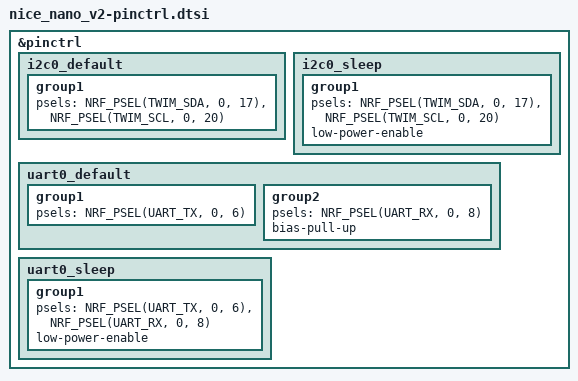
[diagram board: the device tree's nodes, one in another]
/*
 * Copyright (c) 2026 Wafer Pad contributors
 * SPDX-License-Identifier: Apache-2.0
 */

&pinctrl {
	/* Pro Micro I2C pins: D2 = P0.17 (SDA), D3 = P0.20 (SCL).
	 * The nice!nano v2 has NO on-board I2C pull-ups.
	 */
	i2c0_default: i2c0_default {
		group1 {
			psels = <NRF_PSEL(TWIM_SDA, 0, 17)>,
				<NRF_PSEL(TWIM_SCL, 0, 20)>;
		};
	};

	i2c0_sleep: i2c0_sleep {
		group1 {
			psels = <NRF_PSEL(TWIM_SDA, 0, 17)>,
				<NRF_PSEL(TWIM_SCL, 0, 20)>;
			low-power-enable;
		};
	};

	/* Pro Micro serial pins: D1 = P0.06 (TX), D0 = P0.08 (RX). */
	uart0_default: uart0_default {
		group1 {
			psels = <NRF_PSEL(UART_TX, 0, 6)>;
		};
		group2 {
			psels = <NRF_PSEL(UART_RX, 0, 8)>;
			bias-pull-up;
		};
	};

	uart0_sleep: uart0_sleep {
		group1 {
			psels = <NRF_PSEL(UART_TX, 0, 6)>,
				<NRF_PSEL(UART_RX, 0, 8)>;
			low-power-enable;
		};
	};
};
